# GD32G5x3 register map
File version: 1.0
CPU: CM33 r2p1, little endian, MPU, FPU, 4 interrupt priority bits
Registers are 32-bit, read-write, reset 0x0 unless marked. A register's access mark holds for its fields unless they carry their own. Offsets are from the block's base; [hi:lo] are bit positions; {n}, {i} and the like mark numbered series.

## CPDM — Clock phase delay module
Base 0x48022800
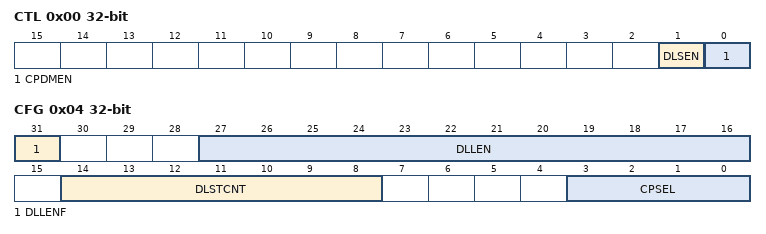
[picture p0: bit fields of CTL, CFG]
0x00 CTL — Control register
  [1] DLSEN — CPDM delay line sample module enable bit
  [0] CPDMEN — CPDM enable bit
0x04 CFG access per field — Configuration register
  [31] DLLENF ro — Valid mark of delay line length
  [27:16] DLLEN ro — Delay line length
  [14:8] DLSTCNT rw — Defines a delay step count for a unit delay UNIT
  [3:0] CPSEL rw — Output clock phase selection

## CRC — Cyclic redundancy checks management unit
Base 0x40023000
0x00 DATA reset 0xFFFFFFFF
  [31:0] DATA — CRC calculation result bits
0x04 FDATA — Free data register
  [7:0] FDATA — Free data register bits
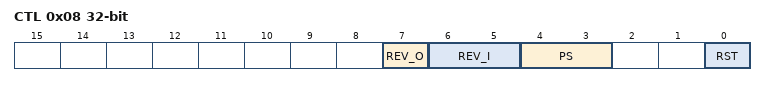
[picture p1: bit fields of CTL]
0x08 CTL — Control register
  [7] REV_O — Reverse output data value in bit order
  [6:5] REV_I — Reverse type for input data
  [4:3] PS — Size of polynomial
  [0] RST — reset bit
0x10 IDATA reset 0xFFFFFFFF — Initialization data register
  [31:0] IDATA — Configurable initial CRC data value
0x14 POLY reset 0x4C11DB7 — Polynomial register
  [31:0] POLY — User configurable polynomial value

## DBG — Debug
Base 0xE0044000
0x00 ID ro — ID code register
  [31:0] ID_CODE — DBG ID code register
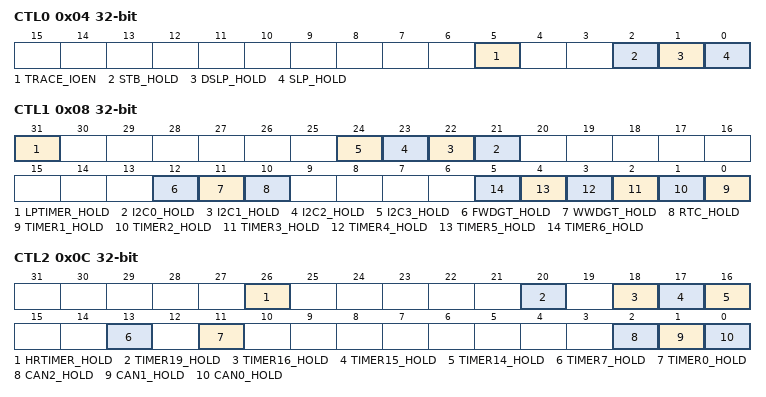
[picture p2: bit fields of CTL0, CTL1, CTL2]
0x04 CTL0 — Control register0
  [5] TRACE_IOEN — Trace pin allocation enable
  [2] STB_HOLD — Standby mode hold bit
  [1] DSLP_HOLD — Deep-sleep mode hold bit
  [0] SLP_HOLD — Sleep mode hold bit
0x08 CTL1 — Control register1
  [31] LPTIMER_HOLD — LPTIMER hold bit
  [n+21] I2C{n}_HOLD (n=0..3) — I2C{n} hold bit
  [12] FWDGT_HOLD — FWDGT hold bit
  [11] WWDGT_HOLD — WWDGT hold bit
  [10] RTC_HOLD — RTC hold bit
  [n-1] TIMER{n}_HOLD (n=1..6) — TIMER{n} hold bit
0x0C CTL2 — Control register2
  [26] HRTIMER_HOLD — HRTIMER hold bit
  [20] TIMER19_HOLD — TIMER19 hold bit
  [18] TIMER16_HOLD — TIMER16 hold bit
  [17] TIMER15_HOLD — TIMER15 hold bit
  [16] TIMER14_HOLD — TIMER14 hold bit
  [13] TIMER7_HOLD — TIMER7 hold bit
  [11] TIMER0_HOLD — TIMER0 hold bit
  [2] CAN2_HOLD — CAN2 hold bit
  [1] CAN1_HOLD — CAN1 hold bit
  [0] CAN0_HOLD — CAN0 hold bit

## DMA0 — DMA0 controller
Base 0x40020000
Same registers: DMA1 0x40020400
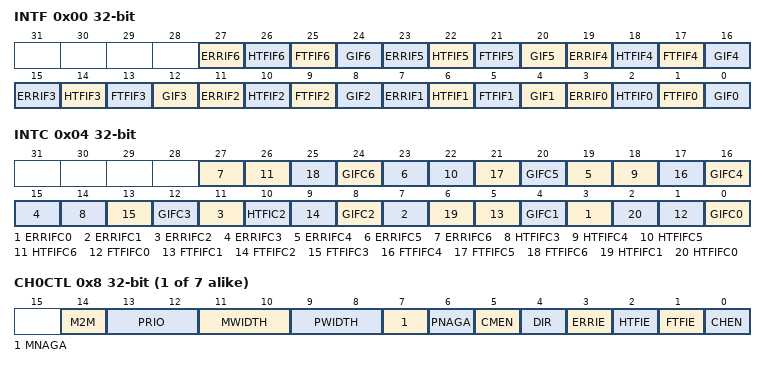
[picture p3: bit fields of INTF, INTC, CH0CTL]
0x00 INTF ro — Interrupt flag register
  [4n+3] ERRIF{n} (n=0..6) — Error flag of channel {n}
  [4n+2] HTFIF{n} (n=0..6) — Half transfer finish flag of channel {n}
  [4n+1] FTFIF{n} (n=0..6) — Full Transfer finish flag of channel {n}
  [4n] GIF{n} (n=0..6) — Global interrupt flag of channel {n}
0x04 INTC wo — Interrupt flag clear register
  [4n+3] ERRIFC{n} (n=0..6) — Clear bit for error flag of channel {n}
  [4n+2] HTFIFC{n} (n=3..6) — Clear bit for half transfer finish flag of channel {n}
  [4n+1] FTFIFC{n} (n=0..6) — Clear bit for full transfer finish flag of channel {n}
  [4n] GIFC{n} (n=0..6) — Clear global interrupt flag of channel {n}
  [10] HTFIC2 — Clear bit for half transfer finish flag of channel 2
  [6] HTFIFC1 — Clear bit for half transfer finish flag of channel 1
  [2] HTFIFC0 — Clear bit for half transfer finish flag of channel 0
{0x8+0x14*i} CH{i}CTL (i=0..6) — Channel {i} control register
  [14] M2M — Memory to Memory mode
  [13:12] PRIO — Priority level
  [11:10] MWIDTH — Transfer data size of memory
  [9:8] PWIDTH — Transfer data size of peripheral
  [7] MNAGA — Next address generation algorithm of memory
  [6] PNAGA — Next address generation algorithm of peripheral
  [5] CMEN — Circular mode enable
  [4] DIR — Transfer direction
  [3] ERRIE — Enable bit for channel error interrupt
  [2] HTFIE — Enable bit for channel half transfer finish interrupt
  [1] FTFIE — Enable bit for channel full transfer finish interrupt
  [0] CHEN — Channel enable
{0xC+0x14*i} CH{i}CNT (i=0..6) — Channel {i} counter register
  [15:0] CNT — Transfer counter
{0x10+0x14*i} CH{i}PADDR (i=0..6) — Channel {i} peripheral base address register
  [31:0] PADDR — Peripheral base address
{0x14+0x14*i} CH{i}MADDR (i=0..6) — Channel {i} memory base address register
  [31:0] MADDR — Memory base address
